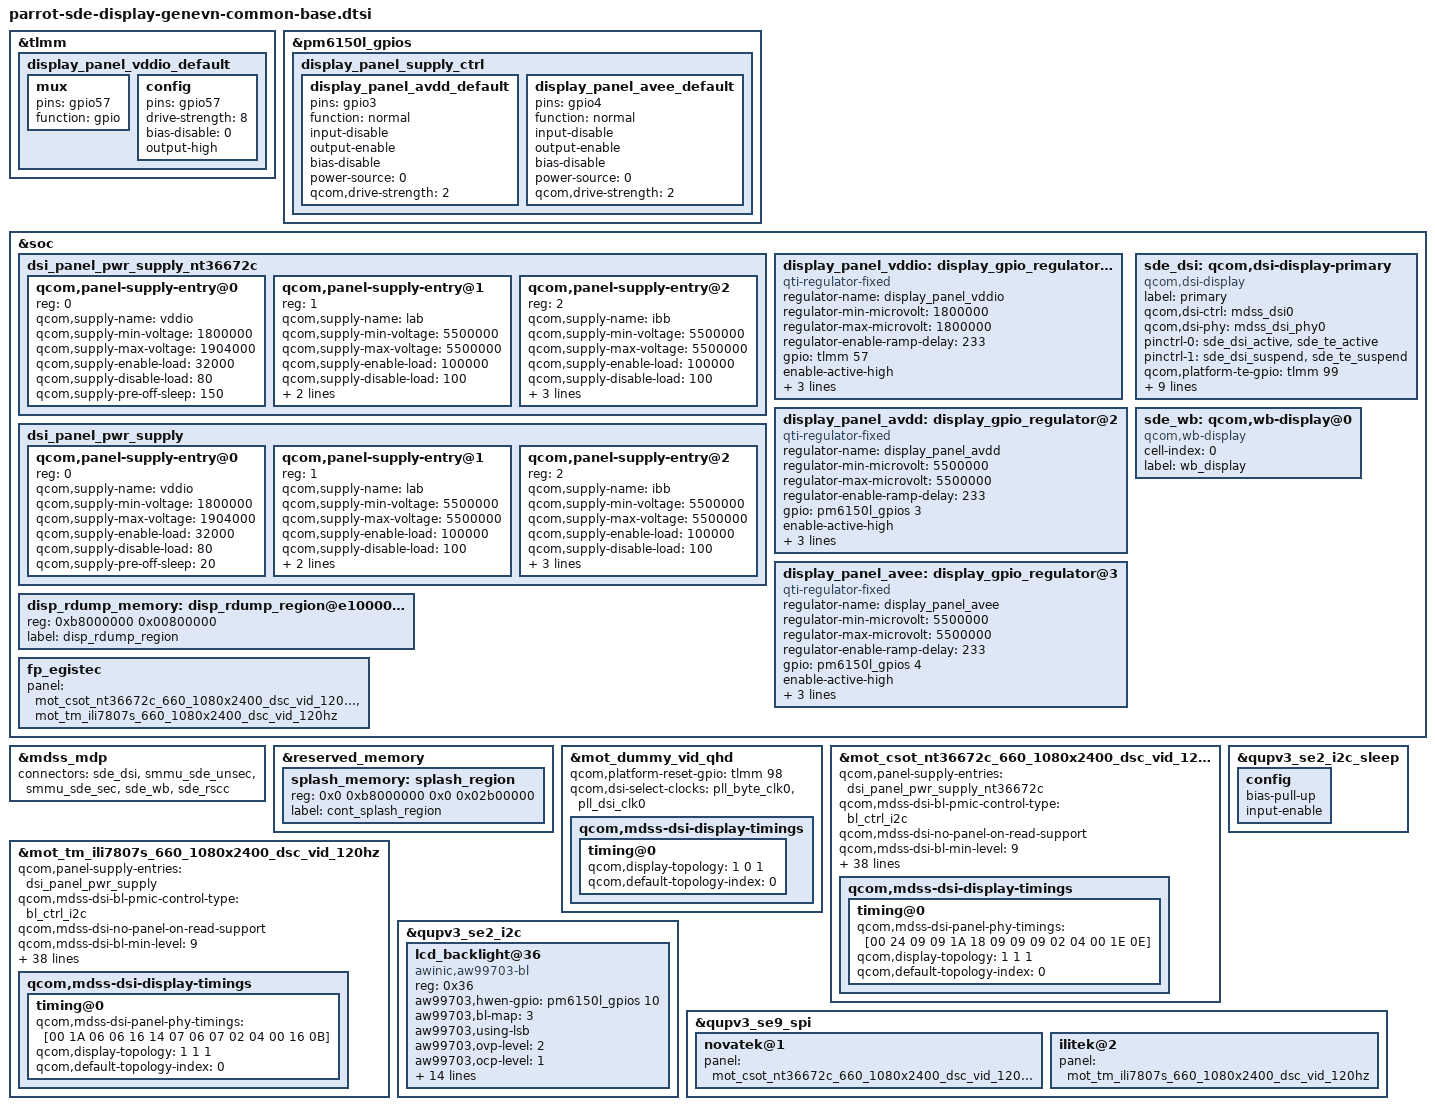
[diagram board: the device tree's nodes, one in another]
/*
   this is original from cape-sde-display-hiphi-common-base.dtsi
*/
#include <dt-bindings/clock/qcom,gcc-parrot.h>
#include <dt-bindings/clock/qcom,rpmh.h>
#include "parrot-sde-display-pinctrl.dtsi"
#include "dsi-panel-mot-dummy-qhd-video.dtsi"
#include <dt-bindings/clock/qcom,dispcc-parrot.h>
#include "dsi-panel-mot-csot-nt36672c-660-1080x2400-dsc-video-120hz-common.dtsi"
#include "dsi-panel-mot-tm-ili7807s-660-1080x2400-dsc-video-120hz-common.dtsi"

&tlmm {
	display_panel_vddio_default: display_panel_vddio_default {
		mux {
			pins = "gpio57";
			function = "gpio";
		};

		config {
			pins = "gpio57";
			drive-strength = <8>;
			bias-disable = <0>;
			output-high;
		};
	};
};

&pm6150l_gpios {
	display_panel_supply_ctrl {
		display_panel_avdd_default: display_panel_avdd_default {
			pins = "gpio3";
			function = "normal";
			input-disable;
			output-enable;
			bias-disable;
			power-source = <0>;
			qcom,drive-strength = <2>;
		};

		display_panel_avee_default: display_panel_avee_default {
			pins = "gpio4";
			function = "normal";
			input-disable;
			output-enable;
			bias-disable;
			power-source = <0>;
			qcom,drive-strength = <2>;
		};
	};
};

&soc {
	dsi_panel_pwr_supply_nt36672c: dsi_panel_pwr_supply_nt36672c {
		#address-cells = <1>;
		#size-cells = <0>;

		qcom,panel-supply-entry@0 {
			reg = <0>;
			qcom,supply-name = "vddio";
			qcom,supply-min-voltage = <1800000>;
			qcom,supply-max-voltage = <1904000>;
			qcom,supply-enable-load = <32000>;
			qcom,supply-disable-load = <80>;
			qcom,supply-pre-off-sleep = <150>;
		};

		qcom,panel-supply-entry@1 {
			reg = <1>;
			qcom,supply-name = "lab";
			qcom,supply-min-voltage = <5500000>;
			qcom,supply-max-voltage = <5500000>;
			qcom,supply-enable-load = <100000>;
			qcom,supply-disable-load = <100>;
			qcom,supply-pre-on-sleep = <3>;
			qcom,supply-post-on-sleep = <3>;
		};

		qcom,panel-supply-entry@2 {
			reg = <2>;
			qcom,supply-name = "ibb";
			qcom,supply-min-voltage = <5500000>;
			qcom,supply-max-voltage = <5500000>;
			qcom,supply-enable-load = <100000>;
			qcom,supply-disable-load = <100>;
			qcom,supply-pre-off-sleep = <3>;
			qcom,supply-post-on-sleep = <8>;
			qcom,supply-post-off-sleep = <3>;
		};
	};

	dsi_panel_pwr_supply: dsi_panel_pwr_supply {
		#address-cells = <1>;
		#size-cells = <0>;

		qcom,panel-supply-entry@0 {
			reg = <0>;
			qcom,supply-name = "vddio";
			qcom,supply-min-voltage = <1800000>;
			qcom,supply-max-voltage = <1904000>;
			qcom,supply-enable-load = <32000>;
			qcom,supply-disable-load = <80>;
			qcom,supply-pre-off-sleep = <20>;
		};

		qcom,panel-supply-entry@1 {
			reg = <1>;
			qcom,supply-name = "lab";
			qcom,supply-min-voltage = <5500000>;
			qcom,supply-max-voltage = <5500000>;
			qcom,supply-enable-load = <100000>;
			qcom,supply-disable-load = <100>;
			qcom,supply-pre-on-sleep = <3>;
			qcom,supply-post-on-sleep = <2>;
		};

		qcom,panel-supply-entry@2 {
			reg = <2>;
			qcom,supply-name = "ibb";
			qcom,supply-min-voltage = <5500000>;
			qcom,supply-max-voltage = <5500000>;
			qcom,supply-enable-load = <100000>;
			qcom,supply-disable-load = <100>;
			qcom,supply-pre-off-sleep = <3>;
			qcom,supply-post-off-sleep = <3>;
			qcom,supply-post-on-sleep = <3>;
		};
	};

	/delete-node/ display_panel_vddio;
	/delete-node/ display_panel_avdd;
	/delete-node/ display_panel_extvdd;

	display_panel_vddio: display_gpio_regulator@1 {
		compatible = "qti-regulator-fixed";
		regulator-name = "display_panel_vddio";
		regulator-min-microvolt = <1800000>;
		regulator-max-microvolt = <1800000>;
		regulator-enable-ramp-delay = <233>;
		gpio = <&tlmm 57 0>;
		enable-active-high;
		regulator-boot-on;
		proxy-supply = <&display_panel_vddio>;
		pinctrl-names = "default";
		pinctrl-0 = <&display_panel_vddio_default>;
	};

	display_panel_avdd: display_gpio_regulator@2 {
		compatible = "qti-regulator-fixed";
		regulator-name = "display_panel_avdd";
		regulator-min-microvolt = <5500000>;
		regulator-max-microvolt = <5500000>;
		regulator-enable-ramp-delay = <233>;
		gpio = <&pm6150l_gpios 3 0>;
		enable-active-high;
		regulator-boot-on;
		proxy-supply = <&display_panel_avdd>;
		pinctrl-names = "default";
		pinctrl-0 = <&display_panel_avdd_default>;
	};

	display_panel_avee: display_gpio_regulator@3 {
		compatible = "qti-regulator-fixed";
		regulator-name = "display_panel_avee";
		regulator-min-microvolt = <5500000>;
		regulator-max-microvolt = <5500000>;
		regulator-enable-ramp-delay = <233>;
		gpio = <&pm6150l_gpios 4 0>;
		enable-active-high;
		regulator-boot-on;
		proxy-supply = <&display_panel_avee>;
		pinctrl-names = "default";
		pinctrl-0 = <&display_panel_avee_default>;
	};

	sde_dsi: qcom,dsi-display-primary {
		compatible = "qcom,dsi-display";
		label = "primary";

		qcom,dsi-ctrl = <&mdss_dsi0>;
		qcom,dsi-phy = <&mdss_dsi_phy0>;

		pinctrl-names = "panel_active", "panel_suspend";
		pinctrl-0 = <&sde_dsi_active &sde_te_active>;
		pinctrl-1 = <&sde_dsi_suspend &sde_te_suspend>;

		qcom,platform-te-gpio = <&tlmm 99 0>;
		qcom,panel-te-source = <0>;

		qcom,mdp = <&mdss_mdp>;
		qcom,demura-panel-id = <0x0122e700 0x000000b0>;
	};
};

&soc {
	sde_wb: qcom,wb-display@0 {
		compatible = "qcom,wb-display";
		cell-index = <0>;
		label = "wb_display";
	};

	disp_rdump_memory: disp_rdump_region@e1000000 {
		reg = <0xb8000000 0x00800000>;
		label = "disp_rdump_region";
	};
};

&sde_dsi {
	clocks = <&mdss_dsi_phy0 0>,
			<&mdss_dsi_phy0 1>,
			 /*
			  * Currently the dsi clock handles are under the dsi
			  * controller DT node. As soon as the controller probe
			  * finishes, the dispcc sync state can get called before
			  * the dsi_display probe potentially disturbing the clock
			  * votes for cont_splash use case. Hence we are no longer
			  * protected by the component model in this case against the
			  * disp cc sync state getting triggered after the dsi_ctrl
			  * probe. To protect against this incorrect sync state trigger
			  * add this dummy MDP clk vote handle to the dsi_display
			  * DT node. Since the dsi_display driver does not parse
			  * MDP clock nodes, no actual vote shall be added and this
			  * change is done just to satisfy sync state requirements.
			  */
			 <&dispcc DISP_CC_MDSS_MDP_CLK>;
	clock-names = "pll_byte_clk0", "pll_dsi_clk0",
			"mdp_core_clk";
};

&mdss_mdp {
	connectors = <&sde_dsi &smmu_sde_unsec &smmu_sde_sec &sde_wb &sde_rscc>;
};

&reserved_memory {
	splash_memory: splash_region {
		reg = <0x0 0xb8000000 0x0 0x02b00000>;
		label = "cont_splash_region";
	};
};

&sde_dsi {
	/delete-property/ vddio-supply;
	/delete-property/ vci-supply;
	/delete-property/ lab-supply;
	/delete-property/ ibb-supply;
	/delete-property/ extvdd-supply;
        vddio-supply = <&display_panel_vddio>;
	lab-supply = <&display_panel_avdd>;
	ibb-supply = <&display_panel_avee>;

	qcom,dsi-default-panel = <&mot_dummy_vid_qhd>;
};

&mot_dummy_vid_qhd {
	qcom,platform-reset-gpio = <&tlmm 98 0>;

	qcom,dsi-select-clocks = "pll_byte_clk0", "pll_dsi_clk0";
	qcom,mdss-dsi-display-timings {
		timing@0 {
			qcom,display-topology = <1 0 1>;
			qcom,default-topology-index = <0>;
		};
	};
};

&mot_csot_nt36672c_660_1080x2400_dsc_vid_120hz{
	qcom,panel-supply-entries = <&dsi_panel_pwr_supply_nt36672c>;
	qcom,mdss-dsi-bl-pmic-control-type = "bl_ctrl_i2c";
	//qcom,mdss-dsi-sec-bl-pmic-control-type = "bl_ctrl_dcs";
	qcom,mdss-dsi-no-panel-on-read-support;
	qcom,mdss-dsi-bl-min-level = <9>;
	qcom,mdss-dsi-bl-max-level = <2047>;
	qcom,mdss-brightness-max-level = <2047>;
	qcom,mdss-dsi-bl-default-level = <1810>;
	qcom,platform-reset-gpio = <&tlmm 98 0>;
	qcom,platform-te-gpio = <&tlmm 99 0>;
	//qcom,platform-vio-enable-gpio = <&tlmm 57 0>;
	qcom,bl-dsc-cmd-state = "dsi_hs_mode";
        qcom,mdss-dsi-bl-inverted-dbv;
	qcom,mdss-dsi-bl-is-exponent;
	qcom,tp_state_check_enable;
	qcom,tp_state_need_reset;

	qcom,ulps-enabled;
	qcom,suspend-ulps-enabled;

	qcom,platform-need-execute-shutdown;

	/*qcom,mdss-dsi-panel-hdr-enable;
	qcom,mdss-dsi-panel-hdr-color-primaries = <14950 15750 34000
					16000 13000 35500 7000 2500>;
	qcom,mdss-dsi-panel-peak-brightness = <5000000>;
	qcom,mdss-dsi-panel-blackness-level = <100>;*/

	qcom,dsi-select-clocks = "pll_byte_clk0", "pll_dsi_clk0";

	qcom,esd-check-enabled;
	qcom,mdss-dsi-panel-status-check-mode = "reg_read";
	qcom,mdss-dsi-panel-status-command = [06 01 00 01 00 00 01 0a];
	qcom,mdss-dsi-panel-status-command-state = "dsi_lp_mode";
	qcom,mdss-dsi-panel-status-value = <0x9c>;
	qcom,mdss-dsi-panel-status-read-length = <1>;

	qcom,mdss-dsi-panel-supplier = "csot";

	qcom,dsi-supported-dfps-list = <120 90 60 30>;
	qcom,mdss-dsi-pan-enable-dynamic-fps;
	qcom,mdss-dsi-pan-fps-update = "dfps_immediate_porch_mode_vfp";

	qcom,mdss-dsi-hbm-on-command = [39 01 00 00 00 00 03 51 07 FF];
	qcom,mdss-dsi-hbm-on-command-state =  "dsi_lp_mode";
	qcom,mdss-dsi-hbm-off-command = [39 01 00 00 00 00 03 51 06 66];
	qcom,mdss-dsi-hbm-off-command-state =  "dsi_lp_mode";
	qcom,mdss-dsi-hbm-type = "lcd-dcs-wled";

	qcom,mdss-dsi-display-timings {
		timing@0 {
			qcom,mdss-dsi-panel-phy-timings = [00 24 09 09 1A 18 09
				09 09 02 04 00 1E 0E];
			qcom,display-topology = <1 1 1>;
			qcom,default-topology-index = <0>;
		};
	};

};

&mot_tm_ili7807s_660_1080x2400_dsc_vid_120hz{
	qcom,panel-supply-entries = <&dsi_panel_pwr_supply>;
	qcom,mdss-dsi-bl-pmic-control-type = "bl_ctrl_i2c";
	//qcom,mdss-dsi-sec-bl-pmic-control-type = "bl_ctrl_dcs";
	qcom,mdss-dsi-no-panel-on-read-support;
	qcom,mdss-dsi-bl-min-level = <9>;
	qcom,mdss-dsi-bl-max-level = <2047>;
	qcom,mdss-brightness-max-level = <2047>;
	qcom,mdss-dsi-bl-default-level = <1810>;
	qcom,platform-reset-gpio = <&tlmm 98 0>;
	qcom,platform-te-gpio = <&tlmm 99 0>;
        touch-rst-pin = <&tlmm 64 0>;
	//qcom,platform-vio-enable-gpio = <&tlmm 57 0>;
	qcom,bl-dsc-cmd-state = "dsi_hs_mode";
        qcom,mdss-dsi-bl-inverted-dbv;
	qcom,mdss-dsi-bl-is-exponent;
	qcom,tp_state_check_enable;

	qcom,ulps-enabled;
	qcom,suspend-ulps-enabled;

	qcom,platform-need-execute-shutdown;

	/*qcom,mdss-dsi-panel-hdr-enable;
	qcom,mdss-dsi-panel-hdr-color-primaries = <14950 15750 34000
					16000 13000 35500 7000 2500>;
	qcom,mdss-dsi-panel-peak-brightness = <5000000>;
	qcom,mdss-dsi-panel-blackness-level = <100>;*/

	qcom,dsi-select-clocks = "pll_byte_clk0", "pll_dsi_clk0";

	qcom,esd-check-enabled;
	qcom,mdss-dsi-panel-status-check-mode = "reg_read";
	qcom,mdss-dsi-panel-status-command = [06 01 00 01 00 00 01 0a];
	qcom,mdss-dsi-panel-status-command-state = "dsi_lp_mode";
	qcom,mdss-dsi-panel-status-value = <0x9c>;
	qcom,mdss-dsi-panel-status-read-length = <1>;

	qcom,mdss-dsi-panel-supplier = "tm";

	qcom,dsi-supported-dfps-list = <120 90 60 30>;
	qcom,mdss-dsi-pan-enable-dynamic-fps;
	qcom,mdss-dsi-pan-fps-update = "dfps_immediate_porch_mode_vfp";

	qcom,mdss-dsi-hbm-on-command = [39 01 00 00 00 00 03 51 03 FF];
	qcom,mdss-dsi-hbm-on-command-state =  "dsi_lp_mode";
	qcom,mdss-dsi-hbm-off-command = [39 01 00 00 00 00 03 51 03 33];
	qcom,mdss-dsi-hbm-off-command-state =  "dsi_lp_mode";
	qcom,mdss-dsi-hbm-type = "lcd-dcs-wled";

	qcom,mdss-dsi-display-timings {
		timing@0 {
			qcom,mdss-dsi-panel-phy-timings = [00 1A 06 06 16 14 07
				06 07 02 04 00 16 0B];
			qcom,display-topology = <1 1 1>;
			qcom,default-topology-index = <0>;
		};
	};

};

&qupv3_se2_i2c {
	status = "ok";

        lcd_backlight@36 {
                compatible = "awinic,aw99703-bl";
                reg = <0x36>;

		/* Awinic, aw99703 */
                aw99703,hwen-gpio = <&pm6150l_gpios 10 0>;
                aw99703,bl-map = <3>; /* brightness map level 1:256,2:1024,3:2048 */
                aw99703,using-lsb;
                aw99703,ovp-level = <2>; /* 0:17.5V, 1:24V, 2:31V, 3:38V, 4:41.5V */
                aw99703,ocp-level = <1>; /* 0:0.9A, 1:1.8A, 2:2.7A, 3:3.4A */
                aw99703,switch-freq = <1>; /* 1000kHz(default) */
                aw99703,auto-freq-high = <0x10>;
                aw99703,auto-freq-low = <0x05>;
                aw99703,bl-fscal-led = <0x17>; /* 23.2mA */
                aw99703,bl-channel = <3>; /* 3 led string */
                aw99703,turn-on-ramp = <0x00>; /* 512us */
                aw99703,turn-off-ramp = <0x04>; /* 8ms */
                aw99703,pwm-trans-dim = <0>; /* 2ms */
                aw99703,i2c-trans-dim = <1>; /* 128ms */
                aw99703,pwm-mode = <1>; /* 1 pwm enable,0 PWM disable */
                aw99703,map-type = <0>; /* 0 exponential, 4 linear */
		current-align-type = <1>;
                aw99703,work-mode = <1>; /* backlight */
		aw99703,default-brightness = <1810>;
	};
};

&qupv3_se2_i2c_sleep {
    config {
        /delete-property/ bias-disable;
        bias-pull-up;
        input-enable;
    };
};

&qupv3_se9_spi {
	novatek@1{
		panel = <&mot_csot_nt36672c_660_1080x2400_dsc_vid_120hz>;
	};
};

&qupv3_se9_spi {
	ilitek@2{
		panel = <&mot_tm_ili7807s_660_1080x2400_dsc_vid_120hz>;
	};
};
&soc {
	fp_egistec {
		panel = <&mot_csot_nt36672c_660_1080x2400_dsc_vid_120hz
			&mot_tm_ili7807s_660_1080x2400_dsc_vid_120hz>;
	};
};
